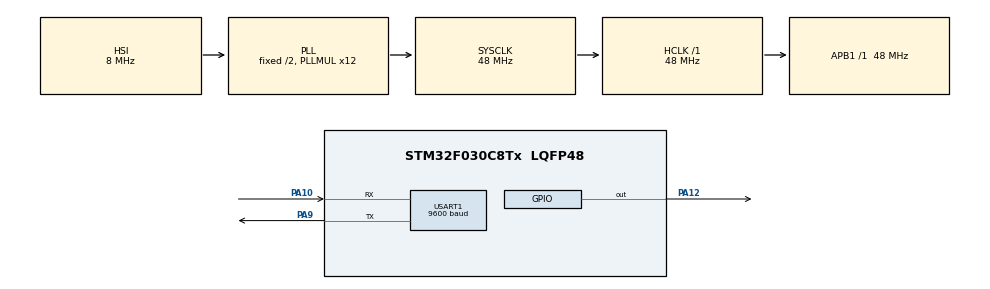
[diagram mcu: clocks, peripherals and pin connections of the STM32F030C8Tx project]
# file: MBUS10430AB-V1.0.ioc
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Mcu.Family=STM32F0
Mcu.Name=STM32F030C8Tx
Mcu.Package=LQFP48
NVIC.TIM16_IRQn=true\:0\:0\:false\:false\:true
NVIC.USART1_IRQn=true\:0\:0\:false\:false\:true
PA10.Mode=Asynchronous
PA10.Signal=USART1_RX
PA12.GPIO_ModeDefaultOutputPP=GPIO_MODE_OUTPUT_PP
PA12.GPIO_PuPd=GPIO_NOPULL
PA12.PinState=GPIO_PIN_SET
PA12.Signal=GPIO_Output
PA13.Mode=Serial_Wire
PA13.Signal=SYS_SWDIO
PA14.Mode=Serial_Wire
PA14.Signal=SYS_SWCLK
PA9.Mode=Asynchronous
PA9.Signal=USART1_TX
ProjectManager.HeapSize=0x200
ProjectManager.StackSize=0x400
ProjectManager.TargetToolchain=MDK-ARM V5
RCC.AHBFreq_Value=48000000
RCC.APB1Freq_Value=48000000
RCC.APB1TimFreq_Value=48000000
RCC.HCLKFreq_Value=48000000
RCC.PLLMUL=RCC_PLL_MUL12
RCC.SYSCLKFreq_VALUE=48000000
RCC.SYSCLKSource=RCC_SYSCLKSOURCE_PLLCLK
TIM16.Period=1000
TIM16.Prescaler=47
USART1.BaudRate=9600
VP_TIM16_VS_ClockSourceINT.Mode=Enable_Timer
board=MBUS10430AB-V1.0

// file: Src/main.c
/**
  ******************************************************************************
  * File Name          : main.c
  * Description        : Main program body
  ******************************************************************************
  *
  * COPYRIGHT(c) 2016 STMicroelectronics
  *
  * Redistribution and use in source and binary forms, with or without modification,
  * are permitted provided that the following conditions are met:
  *   1. Redistributions of source code must retain the above copyright notice,
  *      this list of conditions and the following disclaimer.
  *   2. Redistributions in binary form must reproduce the above copyright notice,
  *      this list of conditions and the following disclaimer in the documentation
  *      and/or other materials provided with the distribution.
  *   3. Neither the name of STMicroelectronics nor the names of its contributors
  *      may be used to endorse or promote products derived from this software
  *      without specific prior written permission.
  *
  * THIS SOFTWARE IS PROVIDED BY THE COPYRIGHT HOLDERS AND CONTRIBUTORS "AS IS"
  * AND ANY EXPRESS OR IMPLIED WARRANTIES, INCLUDING, BUT NOT LIMITED TO, THE
  * IMPLIED WARRANTIES OF MERCHANTABILITY AND FITNESS FOR A PARTICULAR PURPOSE ARE
  * DISCLAIMED. IN NO EVENT SHALL THE COPYRIGHT HOLDER OR CONTRIBUTORS BE LIABLE
  * FOR ANY DIRECT, INDIRECT, INCIDENTAL, SPECIAL, EXEMPLARY, OR CONSEQUENTIAL
  * DAMAGES (INCLUDING, BUT NOT LIMITED TO, PROCUREMENT OF SUBSTITUTE GOODS OR
  * SERVICES; LOSS OF USE, DATA, OR PROFITS; OR BUSINESS INTERRUPTION) HOWEVER
  * CAUSED AND ON ANY THEORY OF LIABILITY, WHETHER IN CONTRACT, STRICT LIABILITY,
  * OR TORT (INCLUDING NEGLIGENCE OR OTHERWISE) ARISING IN ANY WAY OUT OF THE USE
  * OF THIS SOFTWARE, EVEN IF ADVISED OF THE POSSIBILITY OF SUCH DAMAGE.
  *
  ******************************************************************************
  */
#include "main.h"
#include "stm32f0xx_hal.h"
#include "tim.h"
#include "usart.h"
#include "gpio.h"

/* USER CODE BEGIN Includes */
#include "ads1110.h"
/* USER CODE END Includes */

/* USER CODE BEGIN PV */
/* Private variables ---------------------------------------------------------*/
extern uint16_t ADS1110_10Hz;
extern GPIO_TypeDef* I2C_GPIO_PORT;
extern uint16_t I2C_SCL_PIN;
extern uint16_t I2C_SDA_PIN;
/* USER CODE END PV */

void SystemClock_Config(void);
void Error_Handler(void);

/* USER CODE BEGIN PFP */
/* Private function prototypes -----------------------------------------------*/
uint16_t ADC_Data_Buf[4];
float Current[4];
/* USER CODE END PFP */

int main(void)
{

  /* MCU Configuration----------------------------------------------------------*/

  /* Reset of all peripherals, Initializes the Flash interface and the Systick. */
  HAL_Init();

  /* Configure the system clock */
  SystemClock_Config();

  /* Initialize all configured peripherals */
  MX_GPIO_Init();
  MX_TIM16_Init();
  MX_USART1_UART_Init();

  /* USER CODE BEGIN 2 */
  if(HAL_TIM_Base_Start_IT(&htim16) != HAL_OK)
  {
    /* Starting Error */
    while(1);
  }

  I2C_GPIO_PORT = I2C_GPIO_PORT0;
  I2C_SCL_PIN = I2C_SCL0_PIN;
  I2C_SDA_PIN = I2C_SDA0_PIN;
  ADS1110_Init();
  I2C_GPIO_PORT = I2C_GPIO_PORT1;
  I2C_SCL_PIN = I2C_SCL1_PIN;
  I2C_SDA_PIN = I2C_SDA1_PIN;
  ADS1110_Init();
  I2C_GPIO_PORT = I2C_GPIO_PORT2;
  I2C_SCL_PIN = I2C_SCL2_PIN;
  I2C_SDA_PIN = I2C_SDA2_PIN;
  ADS1110_Init();
  I2C_GPIO_PORT = I2C_GPIO_PORT3;
  I2C_SCL_PIN = I2C_SCL3_PIN;
  I2C_SDA_PIN = I2C_SDA3_PIN;
  ADS1110_Init();
  /* USER CODE END 2 */

  /* Infinite loop */
  while (1)
  {

  /* USER CODE BEGIN 3 */
    if(ADS1110_10Hz==0)
    {
      I2C_GPIO_PORT = I2C_GPIO_PORT0;
      I2C_SCL_PIN = I2C_SCL0_PIN;
      I2C_SDA_PIN = I2C_SDA0_PIN;
      ADC_Data_Buf[0] = Get_ADC_Value();
      Current[0] = (float) 2.048 * ADC_Data_Buf[0] / 3276.8;

      I2C_GPIO_PORT = I2C_GPIO_PORT1;
      I2C_SCL_PIN = I2C_SCL1_PIN;
      I2C_SDA_PIN = I2C_SDA1_PIN;
      ADC_Data_Buf[1] = Get_ADC_Value();
      Current[1] = (float) 2.048 * ADC_Data_Buf[1] / 3276.8;

      I2C_GPIO_PORT = I2C_GPIO_PORT2;
      I2C_SCL_PIN = I2C_SCL2_PIN;
      I2C_SDA_PIN = I2C_SDA2_PIN;
      ADC_Data_Buf[2] = Get_ADC_Value();
      Current[2] = (float) 2.048 * ADC_Data_Buf[2] / 3276.8;

      I2C_GPIO_PORT = I2C_GPIO_PORT3;
      I2C_SCL_PIN = I2C_SCL3_PIN;
      I2C_SDA_PIN = I2C_SDA3_PIN;
      ADC_Data_Buf[3] = Get_ADC_Value();
      Current[3] = (float) 2.048 * ADC_Data_Buf[3] / 3276.8;

      ADS1110_10Hz = 1000;
    }
  }
  /* USER CODE END 3 */

}

/** System Clock Configuration
*/
void SystemClock_Config(void)
{

  RCC_OscInitTypeDef RCC_OscInitStruct;
  RCC_ClkInitTypeDef RCC_ClkInitStruct;
  RCC_PeriphCLKInitTypeDef PeriphClkInit;

    /**Initializes the CPU, AHB and APB busses clocks
    */
  RCC_OscInitStruct.OscillatorType = RCC_OSCILLATORTYPE_HSI;
  RCC_OscInitStruct.HSIState = RCC_HSI_ON;
  RCC_OscInitStruct.HSICalibrationValue = 16;
  RCC_OscInitStruct.PLL.PLLState = RCC_PLL_ON;
  RCC_OscInitStruct.PLL.PLLSource = RCC_PLLSOURCE_HSI;
  RCC_OscInitStruct.PLL.PLLMUL = RCC_PLL_MUL12;
  RCC_OscInitStruct.PLL.PREDIV = RCC_PREDIV_DIV1;
  if (HAL_RCC_OscConfig(&RCC_OscInitStruct) != HAL_OK)
  {
    Error_Handler();
  }

    /**Initializes the CPU, AHB and APB busses clocks
    */
  RCC_ClkInitStruct.ClockType = RCC_CLOCKTYPE_HCLK|RCC_CLOCKTYPE_SYSCLK
                              |RCC_CLOCKTYPE_PCLK1;
  RCC_ClkInitStruct.SYSCLKSource = RCC_SYSCLKSOURCE_PLLCLK;
  RCC_ClkInitStruct.AHBCLKDivider = RCC_SYSCLK_DIV1;
  RCC_ClkInitStruct.APB1CLKDivider = RCC_HCLK_DIV1;

  if (HAL_RCC_ClockConfig(&RCC_ClkInitStruct, FLASH_LATENCY_1) != HAL_OK)
  {
    Error_Handler();
  }

  PeriphClkInit.PeriphClockSelection = RCC_PERIPHCLK_USART1;
  PeriphClkInit.Usart1ClockSelection = RCC_USART1CLKSOURCE_PCLK1;
  if (HAL_RCCEx_PeriphCLKConfig(&PeriphClkInit) != HAL_OK)
  {
    Error_Handler();
  }

    /**Configure the Systick interrupt time
    */
  HAL_SYSTICK_Config(HAL_RCC_GetHCLKFreq()/1000);

    /**Configure the Systick
    */
  HAL_SYSTICK_CLKSourceConfig(SYSTICK_CLKSOURCE_HCLK);

  /* SysTick_IRQn interrupt configuration */
  HAL_NVIC_SetPriority(SysTick_IRQn, 0, 0);
}

void Error_Handler(void)
{
  while(1)
  {
  }
}

/************************ (C) COPYRIGHT STMicroelectronics *****END OF FILE****/
